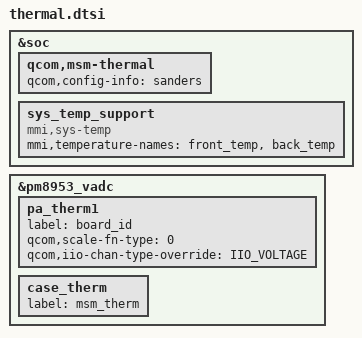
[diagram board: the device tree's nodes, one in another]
&soc {
	qcom,msm-thermal {
		qcom,config-info = "sanders";
	};

	sys_temp_support {
		compatible = "mmi,sys-temp";
		mmi,temperature-names = "front_temp",
					"back_temp";
		status = "ok";
	};
};

&pm8953_vadc {
	pa_therm1 {
		label = "board_id";
		qcom,scale-fn-type = <0>;
		qcom,iio-chan-type-override = "IIO_VOLTAGE";
		/delete-property/ qcom,vadc-thermal-node;
	};

	case_therm {
		label = "msm_therm";
	};
};
